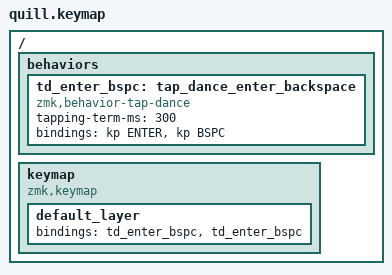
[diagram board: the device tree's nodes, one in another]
/*
 * Quill Keymap - 2-Button Layout (SIMPLIFIED - No Hold Behaviors)
 * 
 * Button A & B:
 *   - Single tap: Enter
 *   - Double tap: Backspace
 * 
 * This version REMOVES hold-tap to prevent stuck keys.
 * We'll add modifiers back once basic tap/double-tap works reliably.
 */

#include <behaviors.dtsi>
#include <dt-bindings/zmk/keys.h>

/ {
    behaviors {
        // Tap-dance: single tap = Enter, double tap = Backspace
        td_enter_bspc: tap_dance_enter_backspace {
            compatible = "zmk,behavior-tap-dance";
            #binding-cells = <0>;
            tapping-term-ms = <300>;
            bindings = <&kp ENTER>, <&kp BSPC>;
        };
    };

    keymap {
        compatible = "zmk,keymap";

        default_layer {
            bindings = <
                &td_enter_bspc    &td_enter_bspc
            >;
        };
    };
};
